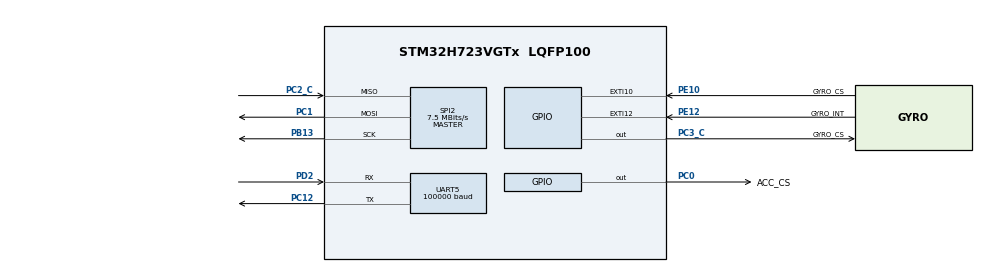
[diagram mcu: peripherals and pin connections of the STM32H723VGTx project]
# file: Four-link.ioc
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CORTEX_M7.default_mode_Activation=1
Dma.Request0=UART5_RX
Dma.Request1=SPI2_RX
Dma.Request2=SPI2_TX
Dma.SPI2_RX.1.Direction=DMA_PERIPH_TO_MEMORY
Dma.SPI2_RX.1.EventEnable=DISABLE
Dma.SPI2_RX.1.FIFOMode=DMA_FIFOMODE_DISABLE
Dma.SPI2_RX.1.Instance=DMA1_Stream0
Dma.SPI2_RX.1.MemDataAlignment=DMA_MDATAALIGN_BYTE
Dma.SPI2_RX.1.MemInc=DMA_MINC_ENABLE
Dma.SPI2_RX.1.Mode=DMA_NORMAL
Dma.SPI2_RX.1.PeriphDataAlignment=DMA_PDATAALIGN_BYTE
Dma.SPI2_RX.1.PeriphInc=DMA_PINC_DISABLE
Dma.SPI2_RX.1.Polarity=HAL_DMAMUX_REQ_GEN_RISING
Dma.SPI2_RX.1.Priority=DMA_PRIORITY_VERY_HIGH
Dma.SPI2_RX.1.RequestNumber=1
Dma.SPI2_RX.1.SignalID=NONE
Dma.SPI2_RX.1.SyncEnable=DISABLE
Dma.SPI2_RX.1.SyncPolarity=HAL_DMAMUX_SYNC_NO_EVENT
Dma.SPI2_RX.1.SyncRequestNumber=1
Dma.SPI2_RX.1.SyncSignalID=NONE
Dma.SPI2_TX.2.Direction=DMA_MEMORY_TO_PERIPH
Dma.SPI2_TX.2.EventEnable=DISABLE
Dma.SPI2_TX.2.FIFOMode=DMA_FIFOMODE_DISABLE
Dma.SPI2_TX.2.Instance=DMA1_Stream1
Dma.SPI2_TX.2.MemDataAlignment=DMA_MDATAALIGN_BYTE
Dma.SPI2_TX.2.MemInc=DMA_MINC_ENABLE
Dma.SPI2_TX.2.Mode=DMA_NORMAL
Dma.SPI2_TX.2.PeriphDataAlignment=DMA_PDATAALIGN_BYTE
Dma.SPI2_TX.2.PeriphInc=DMA_PINC_DISABLE
Dma.SPI2_TX.2.Polarity=HAL_DMAMUX_REQ_GEN_RISING
Dma.SPI2_TX.2.Priority=DMA_PRIORITY_HIGH
Dma.SPI2_TX.2.RequestNumber=1
Dma.SPI2_TX.2.SignalID=NONE
Dma.SPI2_TX.2.SyncEnable=DISABLE
Dma.SPI2_TX.2.SyncPolarity=HAL_DMAMUX_SYNC_NO_EVENT
Dma.SPI2_TX.2.SyncRequestNumber=1
Dma.SPI2_TX.2.SyncSignalID=NONE
Dma.UART5_RX.0.Direction=DMA_PERIPH_TO_MEMORY
Dma.UART5_RX.0.EventEnable=DISABLE
Dma.UART5_RX.0.FIFOMode=DMA_FIFOMODE_DISABLE
Dma.UART5_RX.0.Instance=DMA1_Stream3
Dma.UART5_RX.0.MemDataAlignment=DMA_MDATAALIGN_BYTE
Dma.UART5_RX.0.MemInc=DMA_MINC_ENABLE
Dma.UART5_RX.0.Mode=DMA_CIRCULAR
Dma.UART5_RX.0.PeriphDataAlignment=DMA_PDATAALIGN_BYTE
Dma.UART5_RX.0.PeriphInc=DMA_PINC_DISABLE
Dma.UART5_RX.0.Polarity=HAL_DMAMUX_REQ_GEN_RISING
Dma.UART5_RX.0.Priority=DMA_PRIORITY_LOW
Dma.UART5_RX.0.RequestNumber=1
Dma.UART5_RX.0.SignalID=NONE
Dma.UART5_RX.0.SyncEnable=DISABLE
Dma.UART5_RX.0.SyncPolarity=HAL_DMAMUX_SYNC_NO_EVENT
Dma.UART5_RX.0.SyncRequestNumber=1
Dma.UART5_RX.0.SyncSignalID=NONE
FREERTOS.Tasks01=defaultTask,0,128,StartDefaultTask,Default,NULL,Dynamic,NULL,NULL;cmd,-3,128,cmd_task,As weak,NULL,Dynamic,NULL,NULL
Mcu.Family=STM32H7
Mcu.Name=STM32H723VGTx
Mcu.Package=LQFP100
NVIC.DMA1_Stream0_IRQn=true\:5\:0\:false\:false\:true\:true\:false\:true\:true
NVIC.DMA1_Stream1_IRQn=true\:5\:0\:false\:false\:true\:true\:false\:true\:true
NVIC.DMA1_Stream3_IRQn=true\:5\:0\:false\:false\:true\:true\:false\:true\:true
NVIC.PriorityGroup=NVIC_PRIORITYGROUP_4
NVIC.SPI2_IRQn=true\:5\:0\:false\:false\:true\:true\:false\:true\:true
NVIC.UART5_IRQn=true\:5\:0\:false\:false\:true\:true\:true\:true\:true
PB13.GPIO_Speed=GPIO_SPEED_FREQ_VERY_HIGH
PB13.Mode=Full_Duplex_Master
PB13.Signal=SPI2_SCK
PC0.GPIO_Label=ACC_CS
PC0.GPIO_Speed=GPIO_SPEED_FREQ_VERY_HIGH
PC0.PinState=GPIO_PIN_SET
PC0.Signal=GPIO_Output
PC1.GPIO_Speed=GPIO_SPEED_FREQ_VERY_HIGH
PC1.Mode=Full_Duplex_Master
PC1.Signal=SPI2_MOSI
PC12.GPIO_Speed=GPIO_SPEED_FREQ_LOW
PC12.Mode=Asynchronous
PC12.Signal=UART5_TX
PC2_C.GPIO_Speed=GPIO_SPEED_FREQ_VERY_HIGH
PC2_C.Mode=Full_Duplex_Master
PC2_C.Signal=SPI2_MISO
PC3_C.GPIO_Label=GYRO_CS
PC3_C.GPIO_Speed=GPIO_SPEED_FREQ_VERY_HIGH
PC3_C.PinState=GPIO_PIN_SET
PC3_C.Signal=GPIO_Output
PD2.GPIO_Speed=GPIO_SPEED_FREQ_HIGH
PD2.Mode=Asynchronous
PD2.Signal=UART5_RX
PE10.GPIO_Label=GYRO_CS
PE10.Signal=GPXTI10
PE12.GPIO_Label=GYRO_INT
PE12.Signal=GPXTI12
PH0-OSC_IN.Mode=HSE-External-Oscillator
PH0-OSC_IN.Signal=RCC_OSC_IN
PH1-OSC_OUT.Mode=HSE-External-Oscillator
PH1-OSC_OUT.Signal=RCC_OSC_OUT
ProjectManager.HeapSize=0x200
ProjectManager.StackSize=0x400
ProjectManager.TargetToolchain=CMake
RCC.ADCFreq_Value=48375000
RCC.APB1Freq_Value=120000000
RCC.APB2Freq_Value=120000000
RCC.APB3Freq_Value=120000000
RCC.APB4Freq_Value=120000000
RCC.CortexFreq_Value=480000000
RCC.D1PPRE=RCC_APB3_DIV2
RCC.D2PPRE1=RCC_APB1_DIV2
RCC.D2PPRE2=RCC_APB2_DIV2
RCC.D3PPRE=RCC_APB4_DIV2
RCC.DIVM1=2
RCC.DIVN1=40
RCC.DIVP1=1
RCC.HCLKFreq_Value=240000000
RCC.HPRE=RCC_HCLK_DIV2
RCC.HSE_VALUE=24000000
RCC.PLLFRACN=0
RCC.PLLSourceVirtual=RCC_PLLSOURCE_HSE
RCC.SYSCLKFreq_VALUE=480000000
RCC.SYSCLKSource=RCC_SYSCLKSOURCE_PLLCLK
RCC.USBFreq_Value=240000000
SPI2.BaudRatePrescaler=SPI_BAUDRATEPRESCALER_32
SPI2.CLKPhase=SPI_PHASE_2EDGE
SPI2.CLKPolarity=SPI_POLARITY_HIGH
SPI2.CalculateBaudRate=7.5 MBits/s
SPI2.DataSize=SPI_DATASIZE_8BIT
SPI2.Direction=SPI_DIRECTION_2LINES
SPI2.Mode=SPI_MODE_MASTER
SPI2.VirtualType=VM_MASTER
UART5.BaudRate=100000
UART5.Parity=PARITY_EVEN
UART5.StopBits=UART_STOPBITS_2
UART5.WordLength=WORDLENGTH_9B
VP_FREERTOS_VS_CMSIS_V1.Mode=CMSIS_V1
VP_MEMORYMAP_VS_MEMORYMAP.Mode=CurAppReg
board=custom

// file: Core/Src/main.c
/* USER CODE BEGIN Header */
/**
  ******************************************************************************
  * @file           : main.c
  * @brief          : Main program body
  ******************************************************************************
  * @attention
  *
  * Copyright (c) 2025 STMicroelectronics.
  * All rights reserved.
  *
  * This software is licensed under terms that can be found in the LICENSE file
  * in the root directory of this software component.
  * If no LICENSE file comes with this software, it is provided AS-IS.
  *
  ******************************************************************************
  */
/* USER CODE END Header */
#include "main.h"
#include "cmsis_os.h"
#include "dma.h"
#include "spi.h"
#include "usart.h"
#include "gpio.h"

/* USER CODE BEGIN Includes */
#include  "cmd_fun.h"
/* USER CODE END Includes */

void SystemClock_Config(void);
static void MPU_Config(void);
void MX_FREERTOS_Init(void);

int main(void)
{

  /* MPU Configuration--------------------------------------------------------*/
  MPU_Config();

  /* MCU Configuration--------------------------------------------------------*/

  /* Reset of all peripherals, Initializes the Flash interface and the Systick. */
  HAL_Init();

  /* Configure the system clock */
  SystemClock_Config();

  /* Initialize all configured peripherals */
  MX_GPIO_Init();
  MX_DMA_Init();
  MX_SPI2_Init();
  MX_UART5_Init();
  /* USER CODE BEGIN 2 */
USER_CMD_Init();
  /* USER CODE END 2 */

  /* Call init function for freertos objects (in cmsis_os2.c) */
  MX_FREERTOS_Init();

  /* Start scheduler */
  osKernelStart();

  /* We should never get here as control is now taken by the scheduler */

  /* Infinite loop */
  while (1)
  {

  }
}

void SystemClock_Config(void)
{
  RCC_OscInitTypeDef RCC_OscInitStruct = {0};
  RCC_ClkInitTypeDef RCC_ClkInitStruct = {0};

  /** Supply configuration update enable
  */
  HAL_PWREx_ConfigSupply(PWR_LDO_SUPPLY);

  /** Configure the main internal regulator output voltage
  */
  __HAL_PWR_VOLTAGESCALING_CONFIG(PWR_REGULATOR_VOLTAGE_SCALE0);

  while(!__HAL_PWR_GET_FLAG(PWR_FLAG_VOSRDY)) {}

  /** Initializes the RCC Oscillators according to the specified parameters
  * in the RCC_OscInitTypeDef structure.
  */
  RCC_OscInitStruct.OscillatorType = RCC_OSCILLATORTYPE_HSE;
  RCC_OscInitStruct.HSEState = RCC_HSE_ON;
  RCC_OscInitStruct.PLL.PLLState = RCC_PLL_ON;
  RCC_OscInitStruct.PLL.PLLSource = RCC_PLLSOURCE_HSE;
  RCC_OscInitStruct.PLL.PLLM = 2;
  RCC_OscInitStruct.PLL.PLLN = 40;
  RCC_OscInitStruct.PLL.PLLP = 1;
  RCC_OscInitStruct.PLL.PLLQ = 2;
  RCC_OscInitStruct.PLL.PLLR = 2;
  RCC_OscInitStruct.PLL.PLLRGE = RCC_PLL1VCIRANGE_3;
  RCC_OscInitStruct.PLL.PLLVCOSEL = RCC_PLL1VCOWIDE;
  RCC_OscInitStruct.PLL.PLLFRACN = 0;
  if (HAL_RCC_OscConfig(&RCC_OscInitStruct) != HAL_OK)
  {
    Error_Handler();
  }

  /** Initializes the CPU, AHB and APB buses clocks
  */
  RCC_ClkInitStruct.ClockType = RCC_CLOCKTYPE_HCLK|RCC_CLOCKTYPE_SYSCLK
                              |RCC_CLOCKTYPE_PCLK1|RCC_CLOCKTYPE_PCLK2
                              |RCC_CLOCKTYPE_D3PCLK1|RCC_CLOCKTYPE_D1PCLK1;
  RCC_ClkInitStruct.SYSCLKSource = RCC_SYSCLKSOURCE_PLLCLK;
  RCC_ClkInitStruct.SYSCLKDivider = RCC_SYSCLK_DIV1;
  RCC_ClkInitStruct.AHBCLKDivider = RCC_HCLK_DIV2;
  RCC_ClkInitStruct.APB3CLKDivider = RCC_APB3_DIV2;
  RCC_ClkInitStruct.APB1CLKDivider = RCC_APB1_DIV2;
  RCC_ClkInitStruct.APB2CLKDivider = RCC_APB2_DIV2;
  RCC_ClkInitStruct.APB4CLKDivider = RCC_APB4_DIV2;

  if (HAL_RCC_ClockConfig(&RCC_ClkInitStruct, FLASH_LATENCY_3) != HAL_OK)
  {
    Error_Handler();
  }
}

 /* MPU Configuration */

void MPU_Config(void)
{
  MPU_Region_InitTypeDef MPU_InitStruct = {0};

  /* Disables the MPU */
  HAL_MPU_Disable();

  /** Initializes and configures the Region and the memory to be protected
  */
  MPU_InitStruct.Enable = MPU_REGION_ENABLE;
  MPU_InitStruct.Number = MPU_REGION_NUMBER0;
  MPU_InitStruct.BaseAddress = 0x0;
  MPU_InitStruct.Size = MPU_REGION_SIZE_4GB;
  MPU_InitStruct.SubRegionDisable = 0x87;
  MPU_InitStruct.TypeExtField = MPU_TEX_LEVEL0;
  MPU_InitStruct.AccessPermission = MPU_REGION_NO_ACCESS;
  MPU_InitStruct.DisableExec = MPU_INSTRUCTION_ACCESS_DISABLE;
  MPU_InitStruct.IsShareable = MPU_ACCESS_SHAREABLE;
  MPU_InitStruct.IsCacheable = MPU_ACCESS_NOT_CACHEABLE;
  MPU_InitStruct.IsBufferable = MPU_ACCESS_NOT_BUFFERABLE;

  HAL_MPU_ConfigRegion(&MPU_InitStruct);
  /* Enables the MPU */
  HAL_MPU_Enable(MPU_PRIVILEGED_DEFAULT);

}

void Error_Handler(void)
{
  __disable_irq();
  while (1)
  {
  }
}

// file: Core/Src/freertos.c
/* USER CODE BEGIN Header */
/**
  ******************************************************************************
  * File Name          : freertos.c
  * Description        : Code for freertos applications
  ******************************************************************************
  * @attention
  *
  * Copyright (c) 2025 STMicroelectronics.
  * All rights reserved.
  *
  * This software is licensed under terms that can be found in the LICENSE file
  * in the root directory of this software component.
  * If no LICENSE file comes with this software, it is provided AS-IS.
  *
  ******************************************************************************
  */
/* USER CODE END Header */

#include "FreeRTOS.h"
#include "task.h"
#include "main.h"
#include "cmsis_os.h"

osThreadId defaultTaskHandle;
osThreadId cmdHandle;

void StartDefaultTask(void const * argument);
void cmd_task(void const * argument);

void MX_FREERTOS_Init(void); /* (MISRA C 2004 rule 8.1) */

/* GetIdleTaskMemory prototype (linked to static allocation support) */
void vApplicationGetIdleTaskMemory( StaticTask_t **ppxIdleTaskTCBBuffer, StackType_t **ppxIdleTaskStackBuffer, uint32_t *pulIdleTaskStackSize );

/* USER CODE BEGIN GET_IDLE_TASK_MEMORY */
static StaticTask_t xIdleTaskTCBBuffer;
static StackType_t xIdleStack[configMINIMAL_STACK_SIZE];

void vApplicationGetIdleTaskMemory( StaticTask_t **ppxIdleTaskTCBBuffer, StackType_t **ppxIdleTaskStackBuffer, uint32_t *pulIdleTaskStackSize )
{
  *ppxIdleTaskTCBBuffer = &xIdleTaskTCBBuffer;
  *ppxIdleTaskStackBuffer = &xIdleStack[0];
  *pulIdleTaskStackSize = configMINIMAL_STACK_SIZE;
  /* place for user code */
}
/* USER CODE END GET_IDLE_TASK_MEMORY */

void MX_FREERTOS_Init(void) {

  /* Create the thread(s) */
  /* definition and creation of defaultTask */
  osThreadDef(defaultTask, StartDefaultTask, osPriorityNormal, 0, 128);
  defaultTaskHandle = osThreadCreate(osThread(defaultTask), NULL);

  /* definition and creation of cmd */
  osThreadDef(cmd, cmd_task, osPriorityIdle, 0, 128);
  cmdHandle = osThreadCreate(osThread(cmd), NULL);

}

void StartDefaultTask(void const * argument)
{
  for(;;)
  {
    osDelay(1);
  }
}

__weak void cmd_task(void const * argument)
{
  for(;;)
  {
    osDelay(1);
  }
}
